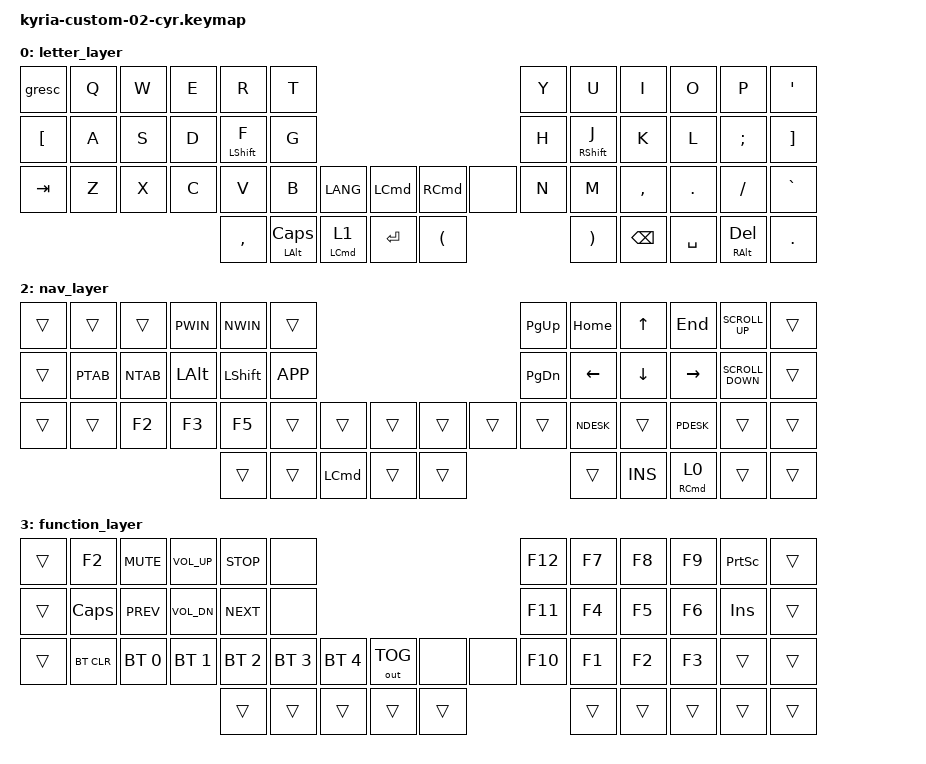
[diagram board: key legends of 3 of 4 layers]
#include <behaviors.dtsi>
#include <dt-bindings/zmk/keys.h>
#include <dt-bindings/zmk/bt.h>
#include <dt-bindings/zmk/outputs.h>

#define LLTR	0
#define LNBR	1
#define LNAV	2
#define LFUN	3

#define PTAB LC(LS(TAB))
#define NTAB LC(TAB)
#define NWIN LC(RIGHT)
#define PWIN LC(LEFT)
#define PDESK LC(LEFT)
#define NDESK LC(RIGHT)
#define LANG LC(SPACE)

&sl {
	release-after-ms = <1000>;
};

/ {
	behaviors {
    // hm: homerow_mods {
    //   compatible = "zmk,behavior-hold-tap";
    //   label = "HOMEROW_MODS";
    //   #binding-cells = <2>;
    //   tapping_term_ms = <200>;
    //   flavor = "tap-preferred";
    //   bindings = <&kp>, <&cp>;
    // };
		hm: homerow_mods {
	    compatible = "zmk,behavior-hold-tap";
	    label = "homerow mods";
	    #binding-cells = <2>;
	    tapping_term_ms = <220>;
	    flavor = "balanced";
	    bindings = <&kp>, <&kp>;
	  };

	  mx: layer_tap_FNC {
			compatible = "zmk,behavior-hold-tap";
			label = "LAYER_TAP_FNC";
			#binding-cells = <2>;
			flavor = "hold-preferred";
			tapping_term_ms = <200>;
			bindings = <&mo>, <&sl>;
		};

		lc: layer_tap_cmd_hold {
			compatible = "zmk,behavior-hold-tap";
			label = "LAYER_TAP_CMD_HOLD";
			#binding-cells = <2>;
			flavor = "hold-preferred";
			tapping_term_ms = <200>;
			bindings = <&kp>, <&to>;
		};

		gresc: grave_escape {
			compatible = "zmk,behavior-mod-morph";
			label = "GRAVE_ESCAPE";
			#binding-cells = <0>;
			bindings = <&kp ESC>, <&kp GRAVE>;
			mods = <(MOD_LGUI|MOD_LSFT|MOD_RGUI|MOD_RSFT)>;
		};
	};

	keymap {
		compatible = "zmk,keymap";

		letter_layer {
			// ---------------------------------------------------------------------------------------------------------------------------------
			// | Esc/~ |  Q  |  W  |  E   |  R   |  T   |                                          |  Y   |  U    |  I    |  O   |   P   |  '   |
			// | [     |  A  |  S  |  D   | F/Sht|  G   |                                          |  H   | J/Sht |  K    |  L   |   ;   |  ]   |
			// | Tab   |  Z  |  X  |  C   |  V   |  B   |  Lang   |  Cmd    |  |   Cmd   |  ---    |  N   |  M    |  ,    |  .   |   /   |  `   |
			//                     |  ,   | ?/Alt|L1/Cmd|  Ret    |   (     |  |   )     |  Bspc   | Spc  | Del/Alt |  .    |
			bindings = <
				&kp gresc   &kp Q &kp W &kp E &kp R 				&kp T                                         &kp Y &kp U  					&kp I			&kp O		&kp P    &kp SQT
				&kp LBKT 		&kp A &kp S &kp D &hm LSHIFT F 	&kp G                                         &kp H &hm RSHFT J			&kp K			&kp L		&kp SEMI &kp RBKT
				&kp TAB   	&kp Z &kp X &kp C &kp V 				&kp B &kp LANG	&kp LCMD    &kp RCMD &none  	&kp N &kp M  					&kp COMMA &kp DOT &kp FSLH &kp GRAVE
										&kp COMMA 	&mt LALT CAPS	&lc LCMD 1	&kp RET		&kp LPAR    &kp RPAR &kp BSPC &kp SPC &mt RALT DEL 	&kp DOT
			>;
		};

		num_layer {
			// ---------------------------------------------------------------------------------------------------------------------------------
			// |  ---  |  /  |  *  |  -   |  +   |  |   |                                          | F12  |  7    |  8    |  9   |  ---  | ---  |
			// |  ---  |  #  |  $  |  @   |  !   |  _   |                                          | F11  |  4    |  5    |  6   |   0   | ---  |
			// |  ---  |  \  |  ^  |  &   |  %   | ---  |   ---   |  ---    |  |   ---   |  ---    | F10  |  1    |  2    |  3   |  ---  | ---  |
			//                     | ---  |  =   |L2/Cmd|   ---   |  ---    |  |   ---   |  ---    | L0   | ---   | ---   |
			bindings = <
				&trans 		&kp FSLH 	&kp STAR  &kp MINUS &kp PLUS 		&kp PIPE                             		&kp F12 &kp N7 &kp N8 &kp N9 &trans &trans
				&trans  	&kp HASH	&kp DLLR 	&kp AT 		&kp EXCL 		&kp UNDER                             	&kp F11	&kp N4 &kp N5 &kp N6 &kp N0 &trans
				&trans 		&kp BSLH 	&kp CARET &kp AMPS 	&kp PRCNT 	&trans 		&trans &trans 	&trans &trans &kp F10 &kp N1 &kp N2 &kp N3 &trans &trans
														&trans  	&kp EQUAL &lc LCMD 2  &trans 		&trans &trans 	&trans &trans &lc RCMD 0 &trans &trans
			>;
		};

		nav_layer {
			// ---------------------------------------------------------------------------------------------------------------------------------
			// | ---  | --- | --- | win+ | win- | ---  |                                          | Pgup | Home |  Up   | End  | ScrUp | ---  |
			// | ---  | Tab+| Tab-| Alt  | Sht  | app  |                                          | Pgdw | Left |  Down | Right| ScrDn | ---  |
			// | ---  | --- | F2  | F3   | F5   | ---  |   ---   |  ---    |  |   ---   |  ---    |      | Predk| ---   | NxDk |  ---  | ---  |
			//                    | ---  | ---  | Cmd  |   Ctl   |  ---    |  |   ---   |  Ins    | L0   | ---  | ---   |
			bindings = <
				&trans &trans 	&trans 		&kp PWIN &kp NWIN  &trans                               &kp PG_UP &kp HOME 	&kp UP   &kp END   &kp K_SCROLL_UP 		&trans
				&trans &kp PTAB &kp NTAB 	&kp LALT &kp LSHFT &kp K_APP                            &kp PG_DN &kp LEFT 	&kp DOWN &kp RIGHT &kp K_SCROLL_DOWN 	&trans
				&trans &trans   &kp F2    &kp F3   &kp F5    &trans &trans &trans  &trans &trans 	&trans   	&kp NDESK &trans   &kp PDESK &trans 						&trans
															&trans  &trans   &kp LCMD     &trans &trans  &trans &INS 		&lc RCMD 0    &trans     &trans
			>;
		};

		function_layer {
			// ---------------------------------------------------------------------------------------------------------------------------------
			// | none  |  F2 | mute| V+   | stp  | ---  |                                       | F12  |  F7   |  F8   |  F9  | Print| none |
			// | none  | caps| Prev| V-   | Next | ---  |                                       | F11  |  F4   |  F5   |  F6  | Ins  | none |
			// | none  | /Ble| Ble0| Ble1 | Ble2 | Ble3 |  Ble4  |  Out    |  |   ---   |  ---  | F10  |  F1   |  F2   |  F3  | ---  | none |
			//                     | ---  | ---  | ---  |  ---   |  ---    |  |   ---   |  ---  | ---  | ---   | ---   |
			bindings = <
				&trans &kp F2     &kp C_MUTE   &kp C_VOL_UP &kp C_STOP   &none                                                &kp F12 &kp F7 &kp F8 &kp F9 &kp PSCRN &trans
				&trans &kp CAPS   &kp C_PREV   &kp C_VOL_DN &kp C_NEXT   &none                                                &kp F11 &kp F4 &kp F5 &kp F6 &kp INS  &trans
				&trans &bt BT_CLR &bt BT_SEL 0 &bt BT_SEL 1 &bt BT_SEL 2 &bt BT_SEL 3 &bt BT_SEL 4 &out OUT_TOG  &none  &none &kp F10 &kp F1 &kp F2 &kp F3 &trans   &trans
																&trans        &trans        &trans           &trans       &trans        &trans &trans &trans &trans &trans
			>;
		};

	};
};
